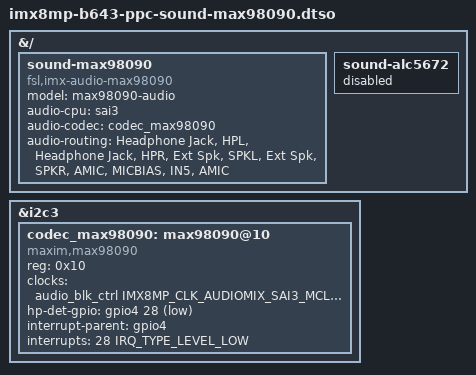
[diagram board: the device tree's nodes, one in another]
// SPDX-License-Identifier: (GPL-2.0+ OR MIT)
/*
 * Copyright 2026 Jason Yang <jasonyang@ieiworld.com>
 */

#include <dt-bindings/gpio/gpio.h>
#include <dt-bindings/interrupt-controller/irq.h>
#include <dt-bindings/clock/imx8mp-clock.h>
#include "imx8mp-pinfunc.h"

/dts-v1/;
/plugin/;

&{/} {
	sound-max98090 {
		compatible = "fsl,imx-audio-max98090";
		model = "max98090-audio";
		audio-cpu = <&sai3>;
		audio-codec = <&codec_max98090>;
		audio-routing =
			"Headphone Jack", "HPL",
			"Headphone Jack", "HPR",
			"Ext Spk", "SPKL",
			"Ext Spk", "SPKR",
			"AMIC", "MICBIAS",
			"IN5", "AMIC";

		status = "okay";
	};

	sound-alc5672 {
		status = "disabled";
	};
};

&i2c3 {
	#address-cells = <1>;
	#size-cells = <0>;

	/delete-node/ codec;

	codec_max98090: max98090@10 {
		compatible = "maxim,max98090";
		reg = <0x10>;
		clocks = <&audio_blk_ctrl IMX8MP_CLK_AUDIOMIX_SAI3_MCLK1>;
		clock-names = "mclk";
		hp-det-gpio = <&gpio4 28 GPIO_ACTIVE_LOW>;
		interrupt-parent = <&gpio4>;
		interrupts = <28 IRQ_TYPE_LEVEL_LOW>;
		status = "okay";
	};
};
